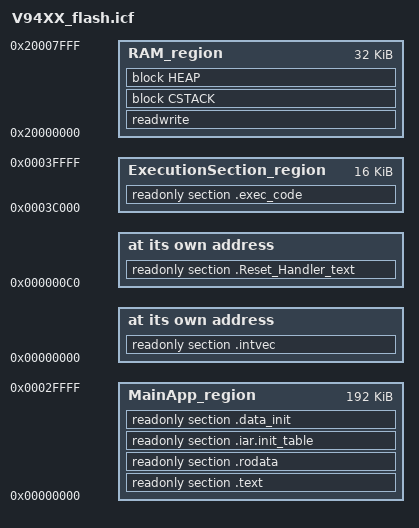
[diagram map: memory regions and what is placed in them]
/*==========================================================
   MAIN FIRMWARE LINKER SCRIPT
   - Base application with loader and main code
   - Execution buffer reserved for dynamic module loading
  ==========================================================*/

/*###ICF### Section handled by ICF editor, don't touch! ****/
/*-Editor annotation file-*/
/* IcfEditorFile="$TOOLKIT_DIR$\config\ide\IcfEditor\cortex_v1_0.xml" */
/*-Specials-*/
define symbol __ICFEDIT_intvec_start__ = 0x00000000;
define symbol __Reset_Handler_text_start__ = 0x000000C0;
/*-Memory Regions-*/
define symbol __ICFEDIT_region_ROM_start__ = 0x00000000;
define symbol __ICFEDIT_region_ROM_end__   = 0x0003FFFF;
define symbol __ICFEDIT_region_RAM_start__ = 0x20000000;
define symbol __ICFEDIT_region_RAM_end__   = 0x20007FFF;
/*-Sizes-*/
define symbol __ICFEDIT_size_cstack__ = 0x1000;
define symbol __ICFEDIT_size_heap__   = 0x400;
/**** End of ICF editor section. ###ICF###*/

define memory mem with size = 4G;

/* === Memory Regions === */
define region MainApp_region       = mem:[from 0x00000000 to 0x0002FFFF]; // 192 KB main firmware
define region ExecutionSection_region = mem:[from 0x0003C000 to 0x0003FFFF]; // 16 KB runtime module window
define region RAM_region           = mem:[from __ICFEDIT_region_RAM_start__ to __ICFEDIT_region_RAM_end__];

/* === Export RAM boundaries for startup === */
export symbol __ICFEDIT_region_RAM_start__;
export symbol __ICFEDIT_region_RAM_end__;

/* === Stack and Heap === */
define block CSTACK with alignment = 8, size = __ICFEDIT_size_cstack__ { };
define block HEAP   with alignment = 8, size = __ICFEDIT_size_heap__ { };

/* === Initialize data === */
initialize by copy { readwrite };
do not initialize { section .noinit };

/* === Vector and Reset === */
place at address mem:__ICFEDIT_intvec_start__ { readonly section .intvec };
place at address mem:__Reset_Handler_text_start__ { readonly section .Reset_Handler_text };

/* === Place Main Firmware Sections === */
place in MainApp_region { 
    readonly section .text,
    readonly section .rodata,
    readonly section .iar.init_table,
    readonly section .data_init
};

/* === Reserve 16 KB region for module execution === */
place in ExecutionSection_region { readonly section .exec_code };

/* === RAM Sections === */
place in RAM_region { readwrite, block CSTACK, block HEAP };
